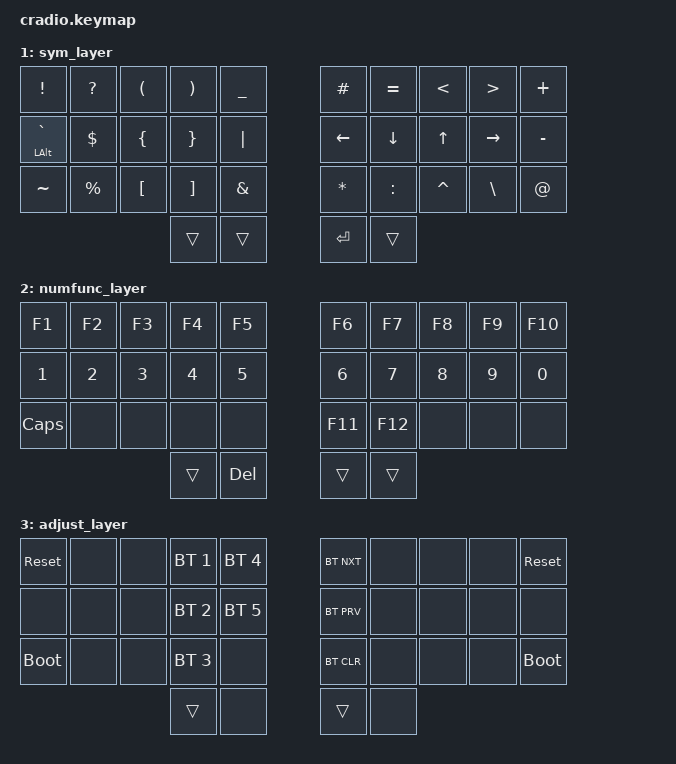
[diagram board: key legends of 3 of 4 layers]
// Copyright (c) 2022 The ZMK Contributors
// SPDX-License-Identifier: MIT

#include <behaviors.dtsi>
#include <dt-bindings/zmk/keys.h>
#include <dt-bindings/zmk/bt.h>

// Layer aliases
#define DEFAULT 0
#define SYM     1
#define NUMFUNC 2
#define ADJUST  3

// Home row mods macro
#define HRML(k1,k2,k3,k4) &ht LGUI k1  &ht LALT k2  &ht LCTRL k3  &ht LSHFT k4
#define HRMR(k1,k2,k3,k4) &ht RSHFT k1  &ht RCTRL k2  &ht RALT k3  &ht RGUI k4
#define ALT_GRAVE &ht LALT GRAVE

// Combos 
#define COMBO(NAME, BINDINGS, KEYPOS) \
  combo_##NAME { \
    timeout-ms = <50>; \
    bindings = <BINDINGS>; \
    key-positions = <KEYPOS>; \
    layers = <DEFAULT>; \
  };

/ {
    behaviors {
        ht: hold_tap {
            label = "hold_tap";
            compatible = "zmk,behavior-hold-tap";
            #binding-cells = <2>;
            flavor = "tap-preferred";
            tapping-term-ms = <220>;
            quick-tap-ms = <150>;
            global-quick-tap;
            bindings = <&kp>, <&kp>;
        };
    };

    combos {
        compatible = "zmk,combos";
        COMBO(esc, &kp ESC, 30 31)
        COMBO(tab, &kp TAB, 32 33)
    };

    conditional_layers {
        compatible = "zmk,conditional-layers";
        tri_layer {
            if-layers = <SYM NUMFUNC>;
            then-layer = <ADJUST>;
        };
    };

    keymap {
        compatible = "zmk,keymap";
       
        default_layer {
       /*
        * Default layer: QWERTY
        *
        * ╭──────────┬──────────┬──────────┬──────────┬──────────╮   ╭──────────┬──────────┬──────────┬──────────┬──────────╮     
        *      Q          W          E          R          T              Y          U          I          O          P
        * ├──────────┼──────────┼──────────┼──────────┼──────────┤   ├──────────┼──────────┼──────────┼──────────┼──────────┤        
        *      A          S          D          F          G              H          J          K          L         ; :
        * ├──────────┼──────────┼──────────┼──────────┼──────────┤   ├──────────┼──────────┼──────────┼──────────┼──────────┤        
        *      Z          X          C          V          B              N          M         , <        . >        / ?
        * ╰──────────┴──────────┴──────────┼──────────┼──────────┤   ├──────────┼──────────┼──────────┴──────────┴──────────╯
        *                                      SYM/      Bksp           NUMFUNC/   Shift
        *                                  │   ' "    │          │   │   Space  │          │   
        *                                  ╰──────────┴──────────╯   ╰──────────┴──────────╯
        */
            bindings = <
        //╭──────────┬──────────┬──────────┬──────────┬──────────╮   ╭──────────┬──────────┬──────────┬──────────┬──────────╮     
             &kp Q      &kp W      &kp E      &kp R      &kp T          &kp Y      &kp U      &kp I      &kp O      &kp P
        //├──────────┼──────────┼──────────┼──────────┼──────────┤   ├──────────┼──────────┼──────────┼──────────┼──────────┤        
             HRML(A,       S,         D,         F)      &kp G          &kp H      HRMR(J,       K,         L,       SEMI)
        //├──────────┼──────────┼──────────┼──────────┼──────────┤   ├──────────┼──────────┼──────────┼──────────┼──────────┤        
             &kp Z      &kp X      &kp C      &kp V      &kp B          &kp N      &kp M     &kp COMMA   &kp DOT   &kp FSLH
        //╰──────────┴──────────┴──────────┼──────────┼──────────┤   ├──────────┼──────────┼──────────┴──────────┴──────────╯
                                            &lt SYM SQT  &kp BSPC    &lt NUMFUNC SPACE  &kp RSHFT
        //                                 │          │          │   │          │          │   
        //                                 ╰──────────┴──────────╯   ╰──────────┴──────────╯
            >;
        };

        sym_layer {
       /*
        * Sym layer: symbols
        *
        * ╭──────────┬──────────┬──────────┬──────────┬──────────╮   ╭──────────┬──────────┬──────────┬──────────┬──────────╮     
        *      !          ?          (          )          _              #          =          <          >          +
        * ├──────────┼──────────┼──────────┼──────────┼──────────┤   ├──────────┼──────────┼──────────┼──────────┼──────────┤        
        *     ` ~         $          {          }          |              ←          ↓          ↑          →         - _
        * ├──────────┼──────────┼──────────┼──────────┼──────────┤   ├──────────┼──────────┼──────────┼──────────┼──────────┤        
        *      ~          %          [          ]          &              *          :          ^          \          @
        * ╰──────────┴──────────┴──────────┼──────────┼──────────┤   ├──────────┼──────────┼──────────┴──────────┴──────────╯
        *                                       --         --           Enter        --
        *                                  │          │          │   │          │          │   
        *                                  ╰──────────┴──────────╯   ╰──────────┴──────────╯
        */
            bindings = <
        //╭──────────┬──────────┬──────────┬──────────┬──────────╮   ╭──────────┬──────────┬──────────┬──────────┬──────────╮     
            &kp EXCL   &kp QMARK  &kp LPAR   &kp RPAR   &kp UNDER      &kp HASH   &kp EQUAL  &kp LT     &kp GT     &kp PLUS
        //├──────────┼──────────┼──────────┼──────────┼──────────┤   ├──────────┼──────────┼──────────┼──────────┼──────────┤        
            ALT_GRAVE  &kp DLLR   &kp LBRC   &kp RBRC   &kp PIPE       &kp LEFT   &kp DOWN   &kp UP     &kp RIGHT  &kp MINUS
        //├──────────┼──────────┼──────────┼──────────┼──────────┤   ├──────────┼──────────┼──────────┼──────────┼──────────┤        
            &kp TILDE  &kp PRCNT  &kp LBKT   &kp RBKT   &kp AMPS       &kp ASTRK  &kp COLON  &kp CARET  &kp BSLH   &kp AT
        //╰──────────┴──────────┴──────────┼──────────┼──────────┤   ├──────────┼──────────┼──────────┴──────────┴──────────╯
                                              &trans     &trans        &kp ENTER   &trans
        //                                 │          │          │   │          │          │   
        //                                 ╰──────────┴──────────╯   ╰──────────┴──────────╯
            >;
        };

        numfunc_layer {
       /*
        * Numfunc layer: numbers, function keys and random
        *
        * ╭──────────┬──────────┬──────────┬──────────┬──────────╮   ╭──────────┬──────────┬──────────┬──────────┬──────────╮     
        *      F1         F2         F3         F4         F5             F6         F7         F8         F9        F10      
        * ├──────────┼──────────┼──────────┼──────────┼──────────┤   ├──────────┼──────────┼──────────┼──────────┼──────────┤        
        *      1          2          3          4          5              6          7          8          9          0
        * ├──────────┼──────────┼──────────┼──────────┼──────────┤   ├──────────┼──────────┼──────────┼──────────┼──────────┤        
        *   CapsLock                                                     F11        F12
        * ╰──────────┴──────────┴──────────┼──────────┼──────────┤   ├──────────┼──────────┼──────────┴──────────┴──────────╯
        *                                       --       Delete           --         --
        *                                  │          │          │   │          │          │   
        *                                  ╰──────────┴──────────╯   ╰──────────┴──────────╯
        */
            bindings = <
        //╭──────────┬──────────┬──────────┬──────────┬──────────╮   ╭──────────┬──────────┬──────────┬──────────┬──────────╮     
             &kp F1     &kp F2     &kp F3     &kp F4     &kp F5         &kp F6     &kp F7     &kp F8     &kp F9     &kp F10
        //├──────────┼──────────┼──────────┼──────────┼──────────┤   ├──────────┼──────────┼──────────┼──────────┼──────────┤        
             &kp N1     &kp N2     &kp N3     &kp N4     &kp N5         &kp N6     &kp N7     &kp N8     &kp N9     &kp N0
        //├──────────┼──────────┼──────────┼──────────┼──────────┤   ├──────────┼──────────┼──────────┼──────────┼──────────┤        
            &kp CAPS    &none      &none      &none      &none          &kp F11    &kp F12    &none      &none      &none
        //╰──────────┴──────────┴──────────┼──────────┼──────────┤   ├──────────┼──────────┼──────────┴──────────┴──────────╯
                                              &trans     &kp DEL        &trans     &trans
        //                                 │          │          │   │          │          │   
        //                                 ╰──────────┴──────────╯   ╰──────────┴──────────╯
            >;
        };

        adjust_layer {
       /*
        * Adjust layer: Bluetooth and reset buttons
        *
        * ╭──────────┬──────────┬──────────┬──────────┬──────────╮   ╭──────────┬──────────┬──────────┬──────────┬──────────╮     
        *    Reset                          Profile 1  Profile 4       Next BT                                      Reset      
        * ├──────────┼──────────┼──────────┼──────────┼──────────┤   ├──────────┼──────────┼──────────┼──────────┼──────────┤        
        *                                   Profile 2  Profile 5       Prev BT                                    
        * ├──────────┼──────────┼──────────┼──────────┼──────────┤   ├──────────┼──────────┼──────────┼──────────┼──────────┤        
        *  Bootloader                       Profile 3                  Clear BT                                   Bootloader
        * ╰──────────┴──────────┴──────────┼──────────┼──────────┤   ├──────────┼──────────┼──────────┴──────────┴──────────╯
        *                                       --                        --
        *                                  │          │          │   │          │          │   
        *                                  ╰──────────┴──────────╯   ╰──────────┴──────────╯
        */
            bindings = <
        //╭──────────┬──────────┬──────────┬──────────┬──────────╮   ╭──────────┬──────────┬──────────┬──────────┬──────────╮     
           &sys_reset   &none      &none  &bt BT_SEL 1 &bt BT_SEL 4   &bt BT_NXT   &none      &none      &none    &sys_reset
        //├──────────┼──────────┼──────────┼──────────┼──────────┤   ├──────────┼──────────┼──────────┼──────────┼──────────┤        
             &none      &none      &none  &bt BT_SEL 2 &bt BT_SEL 5   &bt BT_PRV   &none      &none      &none      &none
        //├──────────┼──────────┼──────────┼──────────┼──────────┤   ├──────────┼──────────┼──────────┼──────────┼──────────┤        
           &bootloader  &none      &none  &bt BT_SEL 3   &none        &bt BT_CLR   &none      &none      &none    &bootloader
        //╰──────────┴──────────┴──────────┼──────────┼──────────┤   ├──────────┼──────────┼──────────┴──────────┴──────────╯
                                              &trans     &none          &trans     &none
        //                                 │          │          │   │          │          │   
        //                                 ╰──────────┴──────────╯   ╰──────────┴──────────╯
            >;
        };       

    //     layer {
    //   /*
    //    * Layer template
    //    *
    //    * ╭──────────┬──────────┬──────────┬──────────┬──────────╮   ╭──────────┬──────────┬──────────┬──────────┬──────────╮     
    //    *   
    //    * ├──────────┼──────────┼──────────┼──────────┼──────────┤   ├──────────┼──────────┼──────────┼──────────┼──────────┤        
    //    *   
    //    * ├──────────┼──────────┼──────────┼──────────┼──────────┤   ├──────────┼──────────┼──────────┼──────────┼──────────┤        
    //    *   
    //    * ╰──────────┴──────────┴──────────┼──────────┼──────────┤   ├──────────┼──────────┼──────────┴──────────┴──────────╯
    //    *
    //    *                                  │          │          │   │          │          │   
    //    *                                  ╰──────────┴──────────╯   ╰──────────┴──────────╯
    //    */
    //        bindings = <
    //    //╭──────────┬──────────┬──────────┬──────────┬──────────╮   ╭──────────┬──────────┬──────────┬──────────┬──────────╮     
    //       
    //    //├──────────┼──────────┼──────────┼──────────┼──────────┤   ├──────────┼──────────┼──────────┼──────────┼──────────┤        
    //       
    //    //├──────────┼──────────┼──────────┼──────────┼──────────┤   ├──────────┼──────────┼──────────┼──────────┼──────────┤        
    //       
    //    //╰──────────┴──────────┴──────────┼──────────┼──────────┤   ├──────────┼──────────┼──────────┴──────────┴──────────╯
    //
    //    //                                 │          │          │   │          │          │   
    //    //                                 ╰──────────┴──────────╯   ╰──────────┴──────────╯
    //        >;
    //    };
    };
};
